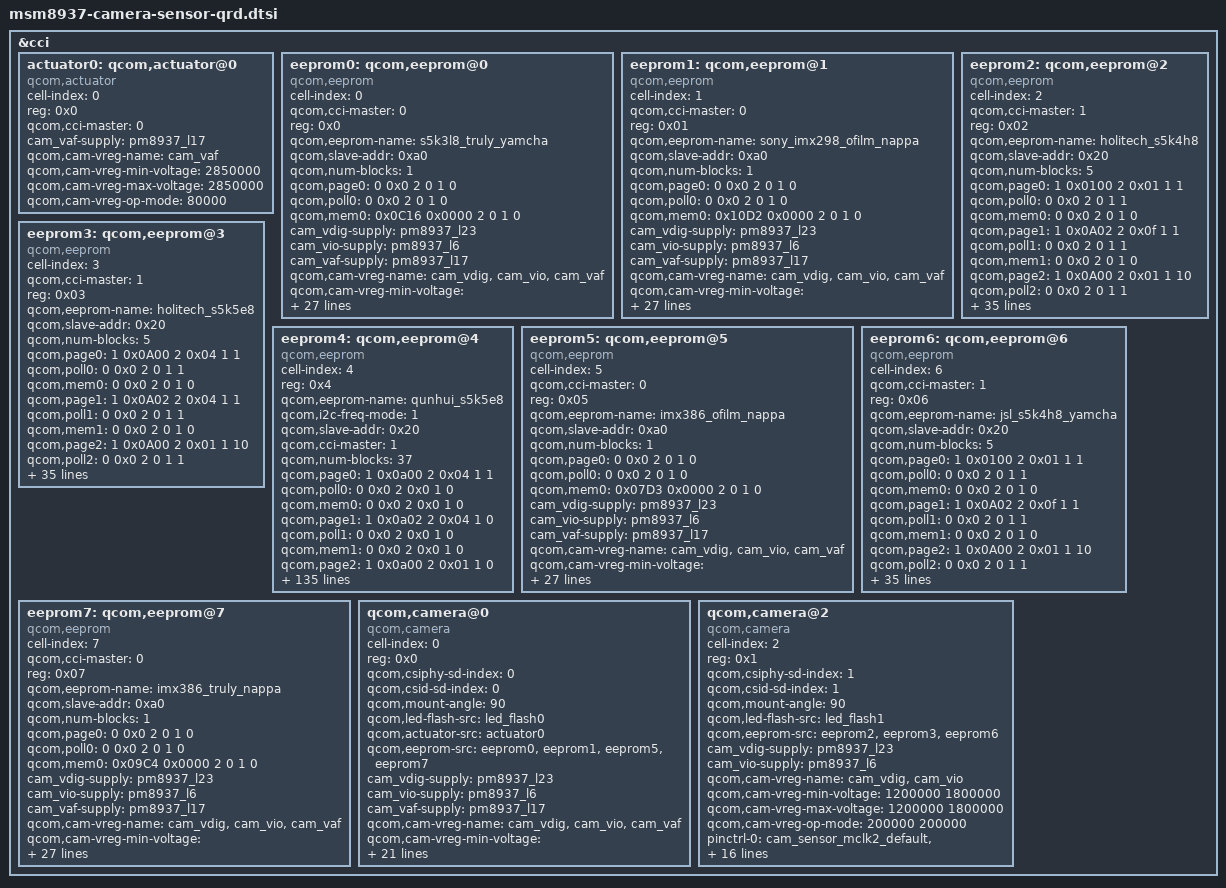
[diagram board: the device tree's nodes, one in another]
/*
 * Copyright (c) 2015-2016, The Linux Foundation. All rights reserved.
 *
 * This program is free software; you can redistribute it and/or modify
 * it under the terms of the GNU General Public License version 2 and
 * only version 2 as published by the Free Software Foundation.
 *
 * This program is distributed in the hope that it will be useful,
 * but WITHOUT ANY WARRANTY; without even the implied warranty of
 * MERCHANTABILITY or FITNESS FOR A PARTICULAR PURPOSE.  See the
 * GNU General Public License for more details.
 */
&cci {
	actuator0: qcom,actuator@0 {
		cell-index = <0>;
		reg = <0x0>;
		compatible = "qcom,actuator";
		qcom,cci-master = <0>;
		cam_vaf-supply = <&pm8937_l17>;
		qcom,cam-vreg-name = "cam_vaf";
		qcom,cam-vreg-min-voltage = <2850000>;
		qcom,cam-vreg-max-voltage = <2850000>;
		qcom,cam-vreg-op-mode = <80000>;
	};
/*
	eeprom0: qcom,eeprom@0 {
		cell-index = <0>;
		compatible = "qcom,eeprom";
		qcom,cci-master = <0>;
		reg = <0x0>;
		cam_vdig-supply = <&pm8937_l23>;
		cam_vana-supply = <&pm8937_l22>;
		cam_vio-supply = <&pm8937_l6>;
		cam_vaf-supply = <&pm8937_l17>;
		qcom,cam-vreg-name = "cam_vdig", "cam_vio", "cam_vana",
							"cam_vaf";
		qcom,cam-vreg-min-voltage = <1200000 0 2800000 2850000>;
		qcom,cam-vreg-max-voltage = <1200000 0 2800000 2850000>;
		qcom,cam-vreg-op-mode = <200000 0 80000 100000>;
		pinctrl-names = "cam_default", "cam_suspend";
		pinctrl-0 = <&cam_sensor_mclk0_default
				&cam_sensor_rear_default>;
		pinctrl-1 = <&cam_sensor_mclk0_sleep &cam_sensor_rear_sleep>;
		gpios = <&tlmm 26 0>,
			<&tlmm 36 0>,
			<&tlmm 35 0>;
		qcom,gpio-reset = <1>;
		qcom,gpio-standby = <2>;
		qcom,gpio-req-tbl-num = <0 1 2>;
		qcom,gpio-req-tbl-flags = <1 0 0>;
		qcom,gpio-req-tbl-label = "CAMIF_MCLK0",
			"CAM_RESET0",
			"CAM_STANDBY0";
		status = "ok";
		clocks = <&clock_gcc clk_mclk0_clk_src>,
				<&clock_gcc clk_gcc_camss_mclk0_clk>;
		clock-names = "cam_src_clk", "cam_clk";
		qcom,clock-rates = <19200000 0>;
	};
*/

	eeprom0: qcom,eeprom@0 {
		compatible = "qcom,eeprom";
		cell-index = <0>;
		qcom,cci-master = <0>;
		reg = <0x0>;
		qcom,eeprom-name = "s5k3l8_truly_yamcha";
		qcom,slave-addr = <0xa0>;
		qcom,num-blocks = <1>;
		qcom,page0 = <0 0x0 2 0 1 0>;
		qcom,poll0 = <0 0x0 2 0 1 0>;
		qcom,mem0 = <0x0C16 0x0000 2 0 1 0>;
        	cam_vdig-supply = <&pm8937_l23>;
		cam_vio-supply = <&pm8937_l6>;
		cam_vaf-supply = <&pm8937_l17>;
		qcom,cam-vreg-name = "cam_vdig","cam_vio","cam_vaf";
		qcom,cam-vreg-min-voltage = <1200000 1800000 2850000>;
		qcom,cam-vreg-max-voltage = <1200000 1800000 2850000>;
		qcom,cam-vreg-op-mode = <105000 105000 100000>;
		pinctrl-names = "cam_default", "cam_suspend";
		pinctrl-0 = <&cam_sensor_mclk0_default &cam_sensor_rear_default>;
		pinctrl-1 = <&cam_sensor_mclk0_sleep &cam_sensor_rear_sleep>;
		gpios = <&tlmm 26 0>,
			<&tlmm 36 0>,
			<&tlmm 27 0>;
		qcom,gpio-reset = <1>;
		qcom,gpio-vana = <2>;
		qcom,gpio-req-tbl-num = <0 1 2>;
		qcom,gpio-req-tbl-flags = <1 0 0>;
		qcom,gpio-req-tbl-label = "CAMIF_MCLK0",
			"CAM_RESET0",
			"CAM_VANA0";
		qcom,cam-power-seq-type = "sensor_gpio",
					  "sensor_gpio", 
					  "sensor_vreg",
					  "sensor_vreg",
					  "sensor_vreg",
					  "sensor_clk",
					  "sensor_gpio";
		qcom,cam-power-seq-val =  "sensor_gpio_reset",
					  "sensor_gpio_vana",
					  "cam_vdig",
					  "cam_vio",
					  "cam_vaf",
					  "sensor_cam_mclk",
					  "sensor_gpio_reset";
		qcom,cam-power-seq-cfg-val = <0 1 1 1 1 24000000 1>;
		qcom,cam-power-seq-delay = <1 1 1 0 5 1 18>;

		status = "ok";

		clocks = <&clock_gcc clk_mclk0_clk_src>,
				<&clock_gcc clk_gcc_camss_mclk0_clk>;
		clock-names = "cam_src_clk", "cam_clk";
		qcom,clock-rates = <19200000 0>;
	};

	eeprom1: qcom,eeprom@1 {
		compatible = "qcom,eeprom";
		cell-index = <1>;
		qcom,cci-master = <0>;
		reg = <0x01>;

		qcom,eeprom-name = "sony_imx298_ofilm_nappa";
		qcom,slave-addr = <0xa0>;
		qcom,num-blocks = <1>;
		qcom,page0 = <0 0x0 2 0 1 0>;
		qcom,poll0 = <0 0x0 2 0 1 0>;
		qcom,mem0 = <0x10D2 0x0000 2 0 1 0>;
		cam_vdig-supply = <&pm8937_l23>;
		cam_vio-supply = <&pm8937_l6>;
		cam_vaf-supply = <&pm8937_l17>;
		qcom,cam-vreg-name = "cam_vdig","cam_vio", "cam_vaf";
		qcom,cam-vreg-min-voltage = <1200000 1800000 2850000>;
		qcom,cam-vreg-max-voltage = <1200000 1800000 2850000>;
		qcom,cam-vreg-op-mode = <105000 105000 100000>;
		pinctrl-names = "cam_default", "cam_suspend";
		pinctrl-0 = <&cam_sensor_mclk0_default &cam_sensor_rear_default>;
		pinctrl-1 = <&cam_sensor_mclk0_sleep &cam_sensor_rear_sleep>;

		gpios = <&tlmm 26 0>,
			<&tlmm 36 0>,
			<&tlmm 27 0>;
		qcom,gpio-reset = <1>;
		qcom,gpio-vana = <2>;
		qcom,gpio-req-tbl-num = <0 1 2>;
		qcom,gpio-req-tbl-flags = <1 0 0>;
		qcom,gpio-req-tbl-label = "CAMIF_MCLK0",
			"CAM_RESET0",
			"CAM_VANA0";
		qcom,cam-power-seq-type = "sensor_gpio",
					  "sensor_gpio", 
					  "sensor_vreg",
					  "sensor_vreg",
					  "sensor_vreg",
					  "sensor_clk",
					  "sensor_gpio";
		qcom,cam-power-seq-val =  "sensor_gpio_reset",
					  "sensor_gpio_vana",
					  "cam_vdig",
					  "cam_vio",
					  "cam_vaf",
					  "sensor_cam_mclk",
					  "sensor_gpio_reset";
		qcom,cam-power-seq-cfg-val = <0 1 1 1 1 24000000 1>;
		qcom,cam-power-seq-delay = <1 1 1 0 5 1 18>;

		status = "ok";

		clocks = <&clock_gcc clk_mclk0_clk_src>,
				<&clock_gcc clk_gcc_camss_mclk0_clk>;
		clock-names = "cam_src_clk", "cam_clk";
		qcom,clock-rates = <19200000 0>;
	};
	
	eeprom2: qcom,eeprom@2 {
		compatible = "qcom,eeprom";
		cell-index = <2>;
		qcom,cci-master = <1>;
		reg = <0x02>;

		qcom,eeprom-name = "holitech_s5k4h8";
		qcom,slave-addr = <0x20>;
		qcom,num-blocks = <5>;

   		//qcom,saddr0 = <0x20>;
		qcom,page0 = <1 0x0100 2 0x01 1 1>;
		qcom,poll0 = <0 0x0 2 0 1 1>;
		qcom,mem0 = <0 0x0 2 0 1 0>;
		
		//BANK 
		//qcom,saddr1 = <0x20>;
		qcom,page1 = <1 0x0A02 2 0x0f 1 1>;
		qcom,poll1 = <0 0x0 2 0 1 1>;
		qcom,mem1 = <0 0x0 2 0 1 0>;

		//qcom,saddr2 = <0x20>;
		qcom,page2 = <1 0x0A00 2 0x01 1 10>;
		qcom,poll2 = <0 0x0 2 0 1 1>;
		qcom,mem2 = <0 0x0 2 0 1 0>;

		//qcom,saddr3 = <0x20>;
		qcom,page3 = <0 0x0A02 2 0x04 1 5>;
		qcom,poll3 = <0 0x0 2 0 1 1>;
		qcom,mem3 = <64 0x0A04 2 0 1 0>;

		//Disable NVM controller
		//qcom,saddr4 = <0x20>;
		qcom,page4 = <1 0x0A00 2 0x00 1 1>;
		qcom,poll4 = <0 0x0 2 0 1 1>;
		qcom,mem4 = <0 0x0 2 0 1 0>;

       	 	cam_vdig-supply = <&pm8937_l23>;
		cam_vio-supply = <&pm8937_l6>;

		qcom,cam-vreg-name = "cam_vdig","cam_vio";
		qcom,cam-vreg-min-voltage = <1200000 1800000>;
		qcom,cam-vreg-max-voltage = <1200000 1800000>;
		qcom,cam-vreg-op-mode = <200000 200000>;
		pinctrl-names = "cam_default", "cam_suspend";
		pinctrl-0 = <&cam_sensor_mclk2_default
				&cam_sensor_front1_default>;
		pinctrl-1 = <&cam_sensor_mclk2_sleep
				&cam_sensor_front1_sleep>;

		gpios = <&tlmm 28 0>,
			<&tlmm 40 0>,
			<&tlmm 27 0>;
		qcom,gpio-reset = <1>;
		qcom,gpio-vana = <2>;
		qcom,gpio-req-tbl-num = <0 1 2>;
		qcom,gpio-req-tbl-flags = <1 0 0>;
		qcom,gpio-req-tbl-label = "CAMIF_MCLK2",
			"CAM_RESET2",
			"CAM_VANA2";
		qcom,cam-power-seq-type = "sensor_gpio",
					  "sensor_gpio", 
					  "sensor_vreg",
					  "sensor_vreg",
					  "sensor_clk",
					  "sensor_gpio";
		qcom,cam-power-seq-val =  "sensor_gpio_reset",
					  "sensor_gpio_vana",
					  "cam_vdig",
					  "cam_vio",
					  "sensor_cam_mclk",
					  "sensor_gpio_reset";
		qcom,cam-power-seq-cfg-val = <0 1 1 1 24000000 1>;
		qcom,cam-power-seq-delay = <1 1 1 0 1 11>;

		status = "ok";
		clocks = <&clock_gcc clk_mclk2_clk_src>,
				<&clock_gcc clk_gcc_camss_mclk2_clk>;
		clock-names = "cam_src_clk", "cam_clk";
		qcom,clock-rates = <19200000 0>;
	};

	eeprom3: qcom,eeprom@3 {
		compatible = "qcom,eeprom";
		cell-index = <3>;
		qcom,cci-master = <1>;
		reg = <0x03>;

		qcom,eeprom-name = "holitech_s5k5e8";
		qcom,slave-addr = <0x20>;
		qcom,num-blocks = <5>;

   		//qcom,saddr0 = <0x20>;
		qcom,page0 = <1 0x0A00 2 0x04 1 1>;
		qcom,poll0 = <0 0x0 2 0 1 1>;
		qcom,mem0 = <0 0x0 2 0 1 0>;

		qcom,page1 = <1 0x0A02 2 0x04 1 1>;
		qcom,poll1 = <0 0x0 2 0 1 1>;
		qcom,mem1 = <0 0x0 2 0 1 0>;

		qcom,page2 = <1 0x0A00 2 0x01 1 10>;
		qcom,poll2 = <0 0x0 2 0 1 1>;
		qcom,mem2 = <0 0x0 2 0 1 0>;

		qcom,page3 = <0 0x0A00 2 0x01 1 1>;
		qcom,poll3 = <0 0x0 2 0 1 1>;
		qcom,mem3 = <64 0x0A04 2 0 1 0>; 

		qcom,page4 = <1 0x0A00 2 0x04 1 1>;
		qcom,poll4 = <0 0x0 2 0 1 1>;
		qcom,mem4= <0 0x0 2 0 1 0>;

       	 	cam_vdig-supply = <&pm8937_l23>;
		cam_vio-supply = <&pm8937_l6>;

		qcom,cam-vreg-name = "cam_vdig","cam_vio";
		qcom,cam-vreg-min-voltage = <1200000 1800000>;
		qcom,cam-vreg-max-voltage = <1200000 1800000>;
		qcom,cam-vreg-op-mode = <200000 200000>;
		pinctrl-names = "cam_default", "cam_suspend";
		pinctrl-0 = <&cam_sensor_mclk2_default
				&cam_sensor_front1_default>;
		pinctrl-1 = <&cam_sensor_mclk2_sleep
				&cam_sensor_front1_sleep>;

		gpios = <&tlmm 28 0>,
			<&tlmm 40 0>,
			<&tlmm 27 0>;
		qcom,gpio-reset = <1>;
		qcom,gpio-vana = <2>;
		qcom,gpio-req-tbl-num = <0 1 2>;
		qcom,gpio-req-tbl-flags = <1 0 0>;
		qcom,gpio-req-tbl-label = "CAMIF_MCLK2",
			"CAM_RESET2",
			"CAM_VANA2";
		qcom,cam-power-seq-type = "sensor_gpio",
					  "sensor_gpio", 
					  "sensor_vreg",
					  "sensor_vreg",
					  "sensor_clk",
					  "sensor_gpio";
		qcom,cam-power-seq-val =  "sensor_gpio_reset",
					  "sensor_gpio_vana",
					  "cam_vdig",
					  "cam_vio",
					  "sensor_cam_mclk",
					  "sensor_gpio_reset";
		qcom,cam-power-seq-cfg-val = <0 1 1 1 24000000 1>;
		qcom,cam-power-seq-delay = <1 1 1 0 1 18>;
		status = "ok";
		clocks = <&clock_gcc clk_mclk2_clk_src>,
				<&clock_gcc clk_gcc_camss_mclk2_clk>;
		clock-names = "cam_src_clk", "cam_clk";
		qcom,clock-rates = <19200000 0>;
	};
	
	eeprom4: qcom,eeprom@4 {
		cell-index = <4>;
		reg = <0x4>;
		qcom,eeprom-name = "qunhui_s5k5e8";
		compatible = "qcom,eeprom";
		qcom,i2c-freq-mode = <1>;
		qcom,slave-addr = <0x20>;
		qcom,cci-master = <1>;
		qcom,num-blocks = <37>;
		//init 
		qcom,page0 = <1 0x0a00 2 0x04 1 1>;
		qcom,poll0 = <0 0x0 2 0x0 1 0>;
		qcom,mem0 = <0 0x0 2 0x0 1 0>;
		//set page 4 
		qcom,page1 = <1 0x0a02 2 0x04 1 0>;
		qcom,poll1 = <0 0x0 2 0x0 1 0>;
		qcom,mem1 = <0 0x0 2 0x0 1 0>;
		//read page 4 value
		qcom,page2 = <1 0x0a00 2 0x01 1 0>;
		qcom,poll2 = <0 0x0 2 0x0 1 5>;
		qcom,mem2 = <64 0x0a04 2 0x0 1 1>;
		//init 
		qcom,page3 = <1 0x0a00 2 0x04 1 1>;
		qcom,poll3 = <0 0x0 2 0x0 1 0>;
		qcom,mem3 = <0 0x0 2 0x0 1 0>;
		//set page 5
		qcom,page4 = <1 0x0a02 2 0x05 1 0>;
		qcom,poll4 = <0 0x0 2 0x0 1 0>;
		qcom,mem4 = <0 0x0 2 0x0 1 0>;
		//read page 5 value
		qcom,page5 = <1 0x0a00 2 0x01 1 0>;
		qcom,poll5 = <0 0x0 2 0x0 1 5>;
		qcom,mem5 = <64 0x0a04 2 0x0 1 1>;
		//init 
		qcom,page6 = <1 0x0a00 2 0x04 1 1>;
		qcom,poll6 = <0 0x0 2 0x0 1 0>;
		qcom,mem6 = <0 0x0 2 0x0 1 0>;
		//set page 6
		qcom,page7 = <1 0x0a02 2 0x06 1 0>;
		qcom,poll7 = <0 0x0 2 0x0 1 0>;
		qcom,mem7 = <0 0x0 2 0x0 1 0>;
		//read page 6 value
		qcom,page8 = <1 0x0a00 2 0x01 1 0>;
		qcom,poll8 = <0 0x0 2 0x0 1 5>;
		qcom,mem8 = <64 0x0a04 2 0x0 1 1>;
		//init 
		qcom,page9 = <1 0x0a00 2 0x04 1 1>;
		qcom,poll9 = <0 0x0 2 0x0 1 0>;
		qcom,mem9 = <0 0x0 2 0x0 1 0>;
		//set page 7
		qcom,page10 = <1 0x0a02 2 0x07 1 0>;
		qcom,poll10 = <0 0x0 2 0x0 1 0>;
		qcom,mem10 = <0 0x0 2 0x0 1 0>;
		//read page 7 value
		qcom,page11 = <1 0x0a00 2 0x01 1 0>;
		qcom,poll11 = <0 0x0 2 0x0 1 5>;
		qcom,mem11 = <64 0x0a04 2 0x0 1 1>;		
		//init 
		qcom,page12 = <1 0x0a00 2 0x04 1 1>;
		qcom,poll12 = <0 0x0 2 0x0 1 0>;
		qcom,mem12 = <0 0x0 2 0x0 1 0>;
		//set page 8
		qcom,page13 = <1 0x0a02 2 0x08 1 0>;
		qcom,poll13 = <0 0x0 2 0x0 1 0>;
		qcom,mem13 = <0 0x0 2 0x0 1 0>;
		//read page 8 value
		qcom,page14 = <1 0x0a00 2 0x01 1 0>;
		qcom,poll14 = <0 0x0 2 0x0 1 5>;
		qcom,mem14 = <64 0x0a04 2 0x0 1 1>;		
		//init 
		qcom,page15 = <1 0x0a00 2 0x04 1 1>;
		qcom,poll15 = <0 0x0 2 0x0 1 0>;
		qcom,mem15 = <0 0x0 2 0x0 1 0>;
		//set page 9
		qcom,page16 = <1 0x0a02 2 0x09 1 0>;
		qcom,poll16 = <0 0x0 2 0x0 1 0>;
		qcom,mem16 = <0 0x0 2 0x0 1 0>;
		//read page 9 value
		qcom,page17 = <1 0x0a00 2 0x01 1 0>;
		qcom,poll17 = <0 0x0 2 0x0 1 5>;
		qcom,mem17 = <64 0x0a04 2 0x0 1 1>;		
		//init 
		qcom,page18 = <1 0x0a00 2 0x04 1 1>;
		qcom,poll18 = <0 0x0 2 0x0 1 0>;
		qcom,mem18 = <0 0x0 2 0x0 1 0>;
		//set page 10
		qcom,page19 = <1 0x0a02 2 0x0a 1 0>;
		qcom,poll19 = <0 0x0 2 0x0 1 0>;
		qcom,mem19 = <0 0x0 2 0x0 1 0>;
		//read page 10 value
		qcom,page20 = <1 0x0a00 2 0x01 1 0>;
		qcom,poll20 = <0 0x0 2 0x0 1 5>;
		qcom,mem20 = <64 0x0a04 2 0x0 1 1>;		
		//init 
		qcom,page21 = <1 0x0a00 2 0x04 1 1>;
		qcom,poll21 = <0 0x0 2 0x0 1 0>;
		qcom,mem21 = <0 0x0 2 0x0 1 0>;
		//set page 11
		qcom,page22 = <1 0x0a02 2 0x0b 1 0>;
		qcom,poll22 = <0 0x0 2 0x0 1 0>;
		qcom,mem22 = <0 0x0 2 0x0 1 0>;
		//read page 11 value
		qcom,page23 = <1 0x0a00 2 0x01 1 0>;
		qcom,poll23 = <0 0x0 2 0x0 1 5>;
		qcom,mem23 = <64 0x0a04 2 0x0 1 1>;		
		//init 
		qcom,page24 = <1 0x0a00 2 0x04 1 1>;
		qcom,poll24 = <0 0x0 2 0x0 1 0>;
		qcom,mem24 = <0 0x0 2 0x0 1 0>;
		//set page 12
		qcom,page25 = <1 0x0a02 2 0x0c 1 0>;
		qcom,poll25 = <0 0x0 2 0x0 1 0>;
		qcom,mem25 = <0 0x0 2 0x0 1 0>;
		//read page 12 value
		qcom,page26 = <1 0x0a00 2 0x01 1 0>;
		qcom,poll26 = <0 0x0 2 0x0 1 5>;
		qcom,mem26 = <64 0x0a04 2 0x0 1 1>;		
		//init 
		qcom,page27 = <1 0x0a00 2 0x04 1 1>;
		qcom,poll27 = <0 0x0 2 0x0 1 0>;
		qcom,mem27 = <0 0x0 2 0x0 1 0>;
		//set page 13
		qcom,page28 = <1 0x0a02 2 0x0d 1 0>;
		qcom,poll28 = <0 0x0 2 0x0 1 0>;
		qcom,mem28 = <0 0x0 2 0x0 1 0>;
		//read page 13 value
		qcom,page29 = <1 0x0a00 2 0x01 1 0>;
		qcom,poll29 = <0 0x0 2 0x0 1 5>;
		qcom,mem29 = <64 0x0a04 2 0x0 1 1>;		
		//init 
		qcom,page30 = <1 0x0a00 2 0x04 1 1>;
		qcom,poll30 = <0 0x0 2 0x0 1 0>;
		qcom,mem30 = <0 0x0 2 0x0 1 0>;
		//set page 14
		qcom,page31 = <1 0x0a02 2 0x0e 1 0>;
		qcom,poll31 = <0 0x0 2 0x0 1 0>;
		qcom,mem31 = <0 0x0 2 0x0 1 0>;
		//read page 14 value
		qcom,page32 = <1 0x0a00 2 0x01 1 0>;
		qcom,poll32 = <0 0x0 2 0x0 1 5>;
		qcom,mem32 = <64 0x0a04 2 0x0 1 1>;			
		//init 
		qcom,page33 = <1 0x0a00 2 0x04 1 1>;
		qcom,poll33 = <0 0x0 2 0x0 1 0>;
		qcom,mem33 = <0 0x0 2 0x0 1 0>;
		//set page 15
		qcom,page34 = <1 0x0a02 2 0x0f 1 0>;
		qcom,poll34 = <0 0x0 2 0x0 1 0>;
		qcom,mem34= <0 0x0 2 0x0 1 0>;
		//read page 15 value
		qcom,page35 = <1 0x0a00 2 0x01 1 0>;
		qcom,poll35 = <0 0x0 2 0x0 1 5>;
		qcom,mem35 = <56 0x0a04 2 0x0 1 1>;		


		
		qcom,page36 = <1 0x0a00 2 0x04 1 0>;
		qcom,poll36 = <0 0x0 2 0x0 1 0>;
		qcom,mem36 = <0 0x0 2 0x0 1 0>;

		qcom,page37 = <1 0x0a00 2 0x00 1 0>;
		qcom,poll37 = <0 0x0 2 0x0 1 0>;
		qcom,mem37 = <0 0x0 2 0x0 1 0>;

		
		cam_vdig-supply = <&pm8937_l23>;
		cam_vio-supply = <&pm8937_l6>;
		//cam_vaf-supply = <&pm8917_l17>;
		qcom,cam-vreg-name = "cam_vdig","cam_vio";
		qcom,cam-vreg-min-voltage = <1200000 1800000>;
		qcom,cam-vreg-max-voltage = <1200000 1800000>;
		qcom,cam-vreg-op-mode = <105000 105000>;
		pinctrl-names = "cam_default", "cam_suspend";
		pinctrl-0 = <&cam_sensor_mclk2_default
				&cam_sensor_front1_default>;
		pinctrl-1 = <&cam_sensor_mclk2_sleep
				&cam_sensor_front1_sleep>;
		gpios = <&tlmm 28 0>,
			<&tlmm 40 0>,
			<&tlmm 27 0>;
		qcom,gpio-reset = <1>;
		qcom,gpio-vana = <2>;
		qcom,gpio-req-tbl-num = <0 1 2>;
		qcom,gpio-req-tbl-flags = <1 0 0>;
		qcom,gpio-req-tbl-label = "CAMIF_MCLK2",
			"CAM_RESET2",
			"CAM_VANA2";
		qcom,cam-power-seq-type = "sensor_gpio",
					  "sensor_gpio", 
					  "sensor_vreg",
					  "sensor_vreg",
					  "sensor_clk",
					  "sensor_gpio";
		qcom,cam-power-seq-val =  "sensor_gpio_reset",
					  "sensor_gpio_vana",
					  "cam_vdig",
					  "cam_vio",
					  "sensor_cam_mclk",
					  "sensor_gpio_reset";
		qcom,cam-power-seq-cfg-val = <0 1 1 1 24000000 1>;
		qcom,cam-power-seq-delay = <1 1 1 0 1 18>;
		status = "ok";
		clocks = <&clock_gcc clk_mclk2_clk_src>,
				<&clock_gcc clk_gcc_camss_mclk2_clk>;
		clock-names = "cam_src_clk", "cam_clk";
		qcom,clock-rates = <19200000 0>;
	};

	eeprom5: qcom,eeprom@5 {
		compatible = "qcom,eeprom";
		cell-index = <5>;
		qcom,cci-master = <0>;
		reg = <0x05>;

		qcom,eeprom-name = "imx386_ofilm_nappa";
		qcom,slave-addr = <0xa0>;
		qcom,num-blocks = <1>;
		qcom,page0 = <0 0x0 2 0 1 0>;
		qcom,poll0 = <0 0x0 2 0 1 0>;
		qcom,mem0 = <0x07D3 0x0000 2 0 1 0>;
		cam_vdig-supply = <&pm8937_l23>;
		cam_vio-supply = <&pm8937_l6>;
		cam_vaf-supply = <&pm8937_l17>;
		qcom,cam-vreg-name = "cam_vdig","cam_vio", "cam_vaf";
		qcom,cam-vreg-min-voltage = <1200000 1800000 2850000>;
		qcom,cam-vreg-max-voltage = <1200000 1800000 2850000>;
		qcom,cam-vreg-op-mode = <105000 105000 100000>;
		pinctrl-names = "cam_default", "cam_suspend";
		pinctrl-0 = <&cam_sensor_mclk0_default &cam_sensor_rear_default>;
		pinctrl-1 = <&cam_sensor_mclk0_sleep &cam_sensor_rear_sleep>;

		gpios = <&tlmm 26 0>,
			<&tlmm 36 0>,
			<&tlmm 27 0>;
		qcom,gpio-reset = <1>;
		qcom,gpio-vana = <2>;
		qcom,gpio-req-tbl-num = <0 1 2>;
		qcom,gpio-req-tbl-flags = <1 0 0>;
		qcom,gpio-req-tbl-label = "CAMIF_MCLK0",
			"CAM_RESET0",
			"CAM_VANA0";
		qcom,cam-power-seq-type = "sensor_gpio",
					  "sensor_gpio",
					  "sensor_vreg",
					  "sensor_vreg",
					  "sensor_vreg",
					  "sensor_clk",
					  "sensor_gpio";
		qcom,cam-power-seq-val =  "sensor_gpio_reset",
					  "sensor_gpio_vana",
					  "cam_vdig",
					  "cam_vio",
					  "cam_vaf",
					  "sensor_cam_mclk",
					  "sensor_gpio_reset";
		qcom,cam-power-seq-cfg-val = <0 1 1 1 1 24000000 1>;
		qcom,cam-power-seq-delay = <1 1 1 0 5 1 18>;

		status = "ok";

		clocks = <&clock_gcc clk_mclk0_clk_src>,
				<&clock_gcc clk_gcc_camss_mclk0_clk>;
		clock-names = "cam_src_clk", "cam_clk";
		qcom,clock-rates = <19200000 0>;
	};	

	eeprom6: qcom,eeprom@6 {
		compatible = "qcom,eeprom";
		cell-index = <6>;
		qcom,cci-master = <1>;
		reg = <0x06>;

		qcom,eeprom-name = "jsl_s5k4h8_yamcha";
		qcom,slave-addr = <0x20>;
		qcom,num-blocks = <5>;

   		//qcom,saddr0 = <0x20>;
		qcom,page0 = <1 0x0100 2 0x01 1 1>;
		qcom,poll0 = <0 0x0 2 0 1 1>;
		qcom,mem0 = <0 0x0 2 0 1 0>;
		
		//BANK 
		//qcom,saddr1 = <0x20>;
		qcom,page1 = <1 0x0A02 2 0x0f 1 1>;
		qcom,poll1 = <0 0x0 2 0 1 1>;
		qcom,mem1 = <0 0x0 2 0 1 0>;

		//qcom,saddr2 = <0x20>;
		qcom,page2 = <1 0x0A00 2 0x01 1 10>;
		qcom,poll2 = <0 0x0 2 0 1 1>;
		qcom,mem2 = <0 0x0 2 0 1 0>;

		//qcom,saddr3 = <0x20>;
		qcom,page3 = <0 0x0A02 2 0x04 1 5>;
		qcom,poll3 = <0 0x0 2 0 1 1>;
		qcom,mem3 = <42 0x0A06 2 0 1 0>;

		//Disable NVM controller
		//qcom,saddr4 = <0x20>;
		qcom,page4 = <1 0x0A00 2 0x00 1 1>;
		qcom,poll4 = <0 0x0 2 0 1 1>;
		qcom,mem4 = <0 0x0 2 0 1 0>;

       	 	cam_vdig-supply = <&pm8937_l23>;
		cam_vio-supply = <&pm8937_l6>;

		qcom,cam-vreg-name = "cam_vdig","cam_vio";
		qcom,cam-vreg-min-voltage = <1200000 1800000>;
		qcom,cam-vreg-max-voltage = <1200000 1800000>;
		qcom,cam-vreg-op-mode = <200000 200000>;
		pinctrl-names = "cam_default", "cam_suspend";
		pinctrl-0 = <&cam_sensor_mclk2_default
				&cam_sensor_front1_default>;
		pinctrl-1 = <&cam_sensor_mclk2_sleep
				&cam_sensor_front1_sleep>;

		gpios = <&tlmm 28 0>,
			<&tlmm 40 0>,
			<&tlmm 27 0>;
		qcom,gpio-reset = <1>;
		qcom,gpio-vana = <2>;
		qcom,gpio-req-tbl-num = <0 1 2>;
		qcom,gpio-req-tbl-flags = <1 0 0>;
		qcom,gpio-req-tbl-label = "CAMIF_MCLK2",
			"CAM_RESET2",
			"CAM_VANA2";
		qcom,cam-power-seq-type = "sensor_gpio",
					  "sensor_gpio", 
					  "sensor_vreg",
					  "sensor_vreg",
					  "sensor_clk",
					  "sensor_gpio";
		qcom,cam-power-seq-val =  "sensor_gpio_reset",
					  "sensor_gpio_vana",
					  "cam_vdig",
					  "cam_vio",
					  "sensor_cam_mclk",
					  "sensor_gpio_reset";
		qcom,cam-power-seq-cfg-val = <0 1 1 1 24000000 1>;
		qcom,cam-power-seq-delay = <1 1 1 0 1 11>;

		status = "ok";
		clocks = <&clock_gcc clk_mclk2_clk_src>,
				<&clock_gcc clk_gcc_camss_mclk2_clk>;
		clock-names = "cam_src_clk", "cam_clk";
		qcom,clock-rates = <19200000 0>;
	};
		
	eeprom7: qcom,eeprom@7 {
		compatible = "qcom,eeprom";
		cell-index = <7>;
		qcom,cci-master = <0>;
		reg = <0x07>;

		qcom,eeprom-name = "imx386_truly_nappa";
		qcom,slave-addr = <0xa0>;
		qcom,num-blocks = <1>;
		qcom,page0 = <0 0x0 2 0 1 0>;
		qcom,poll0 = <0 0x0 2 0 1 0>;
		qcom,mem0 = <0x09C4 0x0000 2 0 1 0>;
		cam_vdig-supply = <&pm8937_l23>;
		cam_vio-supply = <&pm8937_l6>;
		cam_vaf-supply = <&pm8937_l17>;
		qcom,cam-vreg-name = "cam_vdig","cam_vio", "cam_vaf";
		qcom,cam-vreg-min-voltage = <1200000 1800000 2850000>;
		qcom,cam-vreg-max-voltage = <1200000 1800000 2850000>;
		qcom,cam-vreg-op-mode = <105000 105000 100000>;
		pinctrl-names = "cam_default", "cam_suspend";
		pinctrl-0 = <&cam_sensor_mclk0_default &cam_sensor_rear_default>;
		pinctrl-1 = <&cam_sensor_mclk0_sleep &cam_sensor_rear_sleep>;

		gpios = <&tlmm 26 0>,
			<&tlmm 36 0>,
			<&tlmm 27 0>;
		qcom,gpio-reset = <1>;
		qcom,gpio-vana = <2>;
		qcom,gpio-req-tbl-num = <0 1 2>;
		qcom,gpio-req-tbl-flags = <1 0 0>;
		qcom,gpio-req-tbl-label = "CAMIF_MCLK0",
			"CAM_RESET0",
			"CAM_VANA0";
		qcom,cam-power-seq-type = "sensor_gpio",
					  "sensor_gpio",
					  "sensor_vreg",
					  "sensor_vreg",
					  "sensor_vreg",
					  "sensor_clk",
					  "sensor_gpio";
		qcom,cam-power-seq-val =  "sensor_gpio_reset",
					  "sensor_gpio_vana",
					  "cam_vdig",
					  "cam_vio",
					  "cam_vaf",
					  "sensor_cam_mclk",
					  "sensor_gpio_reset";
		qcom,cam-power-seq-cfg-val = <0 1 1 1 1 24000000 1>;
		qcom,cam-power-seq-delay = <1 1 1 0 5 1 18>;

		status = "ok";

		clocks = <&clock_gcc clk_mclk0_clk_src>,
				<&clock_gcc clk_gcc_camss_mclk0_clk>;
		clock-names = "cam_src_clk", "cam_clk";
		qcom,clock-rates = <19200000 0>;
	};
	
/*
	eeprom2: qcom,eeprom@2 {
		cell-index = <2>;
		compatible = "qcom,eeprom";
		reg = <0x02>;
		cam_vdig-supply = <&pm8937_l23>;
		cam_vana-supply = <&pm8937_l22>;
		cam_vio-supply = <&pm8937_l6>;
		cam_vaf-supply = <&pm8937_l17>;
		qcom,cam-vreg-name = "cam_vdig", "cam_vio", "cam_vana",
								"cam_vaf";
		qcom,cam-vreg-min-voltage = <1200000 0 2800000 2850000>;
		qcom,cam-vreg-max-voltage = <1200000 0 2800000 2850000>;
		qcom,cam-vreg-op-mode = <105000 0 80000 100000>;
		qcom,gpio-no-mux = <0>;
		pinctrl-names = "cam_default", "cam_suspend";
		pinctrl-0 = <&cam_sensor_mclk2_default
					&cam_sensor_front1_default>;
		pinctrl-1 = <&cam_sensor_mclk2_sleep
					&cam_sensor_front1_sleep>;
		gpios = <&tlmm 28 0>,
			<&tlmm 40 0>,
			<&tlmm 39 0>;
		qcom,gpio-reset = <1>;
		qcom,gpio-standby = <2>;
		qcom,gpio-req-tbl-num = <0 1 2>;
		qcom,gpio-req-tbl-flags = <1 0 0>;
		qcom,gpio-req-tbl-label = "CAMIF_MCLK2",
					  "CAM_RESET2",
					  "CAM_STANDBY2";
		qcom,cci-master = <0>;
		status = "ok";
		clocks = <&clock_gcc clk_mclk2_clk_src>,
			<&clock_gcc clk_gcc_camss_mclk2_clk>;
		clock-names = "cam_src_clk", "cam_clk";
		qcom,clock-rates = <19200000 0>;
	};
*/

	qcom,camera@0 {
		cell-index = <0>;
		compatible = "qcom,camera";
		reg = <0x0>;
		qcom,csiphy-sd-index = <0>;
		qcom,csid-sd-index = <0>;
		qcom,mount-angle = <90>;

		qcom,led-flash-src = <&led_flash0>;
		qcom,actuator-src = <&actuator0>;
		qcom,eeprom-src = <&eeprom0 &eeprom1 &eeprom5 &eeprom7>;
        	cam_vdig-supply = <&pm8937_l23>;
		cam_vio-supply = <&pm8937_l6>;
		cam_vaf-supply = <&pm8937_l17>;

		qcom,cam-vreg-name = "cam_vdig","cam_vio", "cam_vaf";
		qcom,cam-vreg-min-voltage = <1200000 1800000 2850000>;
		qcom,cam-vreg-max-voltage = <1200000 1800000 2850000>;
		qcom,cam-vreg-op-mode = <200000 200000 100000>;
		pinctrl-names = "cam_default", "cam_suspend";
		pinctrl-0 = <&cam_sensor_mclk0_default
				&cam_sensor_rear_default>;
		pinctrl-1 = <&cam_sensor_mclk0_sleep
				&cam_sensor_rear_sleep>;
		gpios = <&tlmm 26 0>,
			<&tlmm 36 0>,
			<&tlmm 27 0>;
		qcom,gpio-reset = <1>;
		qcom,gpio-vana = <2>;
		qcom,gpio-req-tbl-num = <0 1 2>;
		qcom,gpio-req-tbl-flags = <1 0 0>;
		qcom,gpio-req-tbl-label = "CAMIF_MCLK0",
			"CAM_RESET0",
			"CAM_VANA0";
		qcom,sensor-position = <0>;
		qcom,sensor-mode = <0>;
		qcom,cci-master = <0>;
		status = "ok";

		clocks = <&clock_gcc clk_mclk0_clk_src>,
			<&clock_gcc clk_gcc_camss_mclk0_clk>;
		clock-names = "cam_src_clk", "cam_clk";
		qcom,clock-rates = <24000000 0>;
	};

/*
	qcom,camera@0 {
		cell-index = <0>;
		compatible = "qcom,camera";
		reg = <0x0>;
		qcom,csiphy-sd-index = <0>;
		qcom,csid-sd-index = <0>;
		qcom,mount-angle = <90>;
		qcom,actuator-src = <&actuator0>;
		qcom,led-flash-src = <&led_flash0>;
		qcom,eeprom-src = <&eeprom0>;
		cam_vdig-supply = <&pm8937_l23>;
		cam_vana-supply = <&pm8937_l22>;
		cam_vio-supply = <&pm8937_l6>;
		cam_vaf-supply = <&pm8937_l17>;
		qcom,cam-vreg-name = "cam_vdig", "cam_vio", "cam_vana",
							"cam_vaf";
		qcom,cam-vreg-min-voltage = <1200000 0 2800000 2850000>;
		qcom,cam-vreg-max-voltage = <1200000 0 2800000 2850000>;
		qcom,cam-vreg-op-mode = <200000 0 80000 100000>;
		pinctrl-names = "cam_default", "cam_suspend";
		pinctrl-0 = <&cam_sensor_mclk0_default
				&cam_sensor_rear_default>;
		pinctrl-1 = <&cam_sensor_mclk0_sleep
				&cam_sensor_rear_sleep>;
		gpios = <&tlmm 26 0>,
			<&tlmm 36 0>,
			<&tlmm 35 0>;
		qcom,gpio-reset = <1>;
		qcom,gpio-standby = <2>;
		qcom,gpio-req-tbl-num = <0 1 2>;
		qcom,gpio-req-tbl-flags = <1 0 0>;
		qcom,gpio-req-tbl-label = "CAMIF_MCLK0",
			"CAM_RESET0",
			"CAM_STANDBY0";
		qcom,sensor-position = <0>;
		qcom,sensor-mode = <0>;
		qcom,cci-master = <0>;
		clocks = <&clock_gcc clk_mclk0_clk_src>,
			<&clock_gcc clk_gcc_camss_mclk0_clk>;
		clock-names = "cam_src_clk", "cam_clk";
		qcom,clock-rates = <24000000 0>;
	};
*/
/*
	qcom,camera@2 {
		cell-index = <2>;
		compatible = "qcom,camera";
		reg = <0x01>;
		qcom,csiphy-sd-index = <1>;
		qcom,csid-sd-index = <1>;
		qcom,eeprom-src = <&eeprom2>;
		qcom,mount-angle = <270>;
		cam_vdig-supply = <&pm8937_l23>;
		cam_vana-supply = <&pm8937_l22>;
		cam_vio-supply = <&pm8937_l6>;
		qcom,cam-vreg-name = "cam_vdig", "cam_vio", "cam_vana";
		qcom,cam-vreg-min-voltage = <1200000 0 2800000>;
		qcom,cam-vreg-max-voltage = <1200000 0 2800000>;
		qcom,cam-vreg-op-mode = <105000 0 80000>;
		qcom,gpio-no-mux = <0>;
		pinctrl-names = "cam_default", "cam_suspend";
		pinctrl-0 = <&cam_sensor_mclk2_default
				&cam_sensor_front1_default>;
		pinctrl-1 = <&cam_sensor_mclk2_sleep
				&cam_sensor_front1_sleep>;
		gpios = <&tlmm 28 0>,
			<&tlmm 40 0>,
			<&tlmm 39 0>;
		qcom,gpio-reset = <1>;
		qcom,gpio-standby = <2>;
		qcom,gpio-req-tbl-num = <0 1 2>;
		qcom,gpio-req-tbl-flags = <1 0 0>;
		qcom,gpio-req-tbl-label = "CAMIF_MCLK2",
					  "CAM_RESET2",
					  "CAM_STANDBY2";
		qcom,sensor-position = <1>;
		qcom,sensor-mode = <0>;
		qcom,cci-master = <0>;
		clocks = <&clock_gcc clk_mclk2_clk_src>,
			<&clock_gcc clk_gcc_camss_mclk2_clk>;
		clock-names = "cam_src_clk", "cam_clk";
		qcom,clock-rates = <24000000 0>;
	};
*/

	qcom,camera@2 {
		cell-index = <2>;
		compatible = "qcom,camera";
		reg = <0x1>;
		qcom,csiphy-sd-index = <1>;
		qcom,csid-sd-index = <1>;
		qcom,mount-angle = <90>;

		qcom,led-flash-src = <&led_flash1>;
		//qcom,actuator-src = <&actuator0>;
		qcom,eeprom-src = <&eeprom2 &eeprom3  &eeprom6>;
       		cam_vdig-supply = <&pm8937_l23>; 
		cam_vio-supply = <&pm8937_l6>;
		//cam_vaf-supply = <&pm8937_l17>;

		qcom,cam-vreg-name = "cam_vdig","cam_vio";
		qcom,cam-vreg-min-voltage = <1200000 1800000>;
		qcom,cam-vreg-max-voltage = <1200000 1800000>;
		qcom,cam-vreg-op-mode = <200000 200000>;
		pinctrl-names = "cam_default", "cam_suspend";
		pinctrl-0 = <&cam_sensor_mclk2_default
				&cam_sensor_front1_default>;
		pinctrl-1 = <&cam_sensor_mclk2_sleep
				&cam_sensor_front1_sleep>;
		gpios = <&tlmm 28 0>,
			<&tlmm 40 0>,
			<&tlmm 27 0>;
		qcom,gpio-reset = <1>;
		qcom,gpio-vana = <2>;
		qcom,gpio-req-tbl-num = <0 1 2>;
		qcom,gpio-req-tbl-flags = <1 0 0>;
		qcom,gpio-req-tbl-label = "CAMIF_MCLK2",
			"CAM_RESET2",
			"CAM_VANA2";
		qcom,sensor-position = <1>;
		qcom,sensor-mode = <1>;
		qcom,cci-master = <1>;
		status = "ok";

		clocks = <&clock_gcc clk_mclk2_clk_src>,
			<&clock_gcc clk_gcc_camss_mclk2_clk>;
		clock-names = "cam_src_clk", "cam_clk";
		qcom,clock-rates = <24000000 0>;
	};
};
